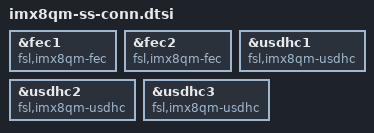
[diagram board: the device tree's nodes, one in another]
&fec1 {
	compatible = "fsl,imx8qm-fec", "fsl,imx6sx-fec";
};
&fec2 {
	compatible = "fsl,imx8qm-fec", "fsl,imx6sx-fec";
};
&usdhc1 {
	compatible = "fsl,imx8qm-usdhc", "fsl,imx8qxp-usdhc", "fsl,imx7d-usdhc";
};
&usdhc2 {
	compatible = "fsl,imx8qm-usdhc", "fsl,imx8qxp-usdhc", "fsl,imx7d-usdhc";
};
&usdhc3 {
	compatible = "fsl,imx8qm-usdhc", "fsl,imx8qxp-usdhc", "fsl,imx7d-usdhc";
};
